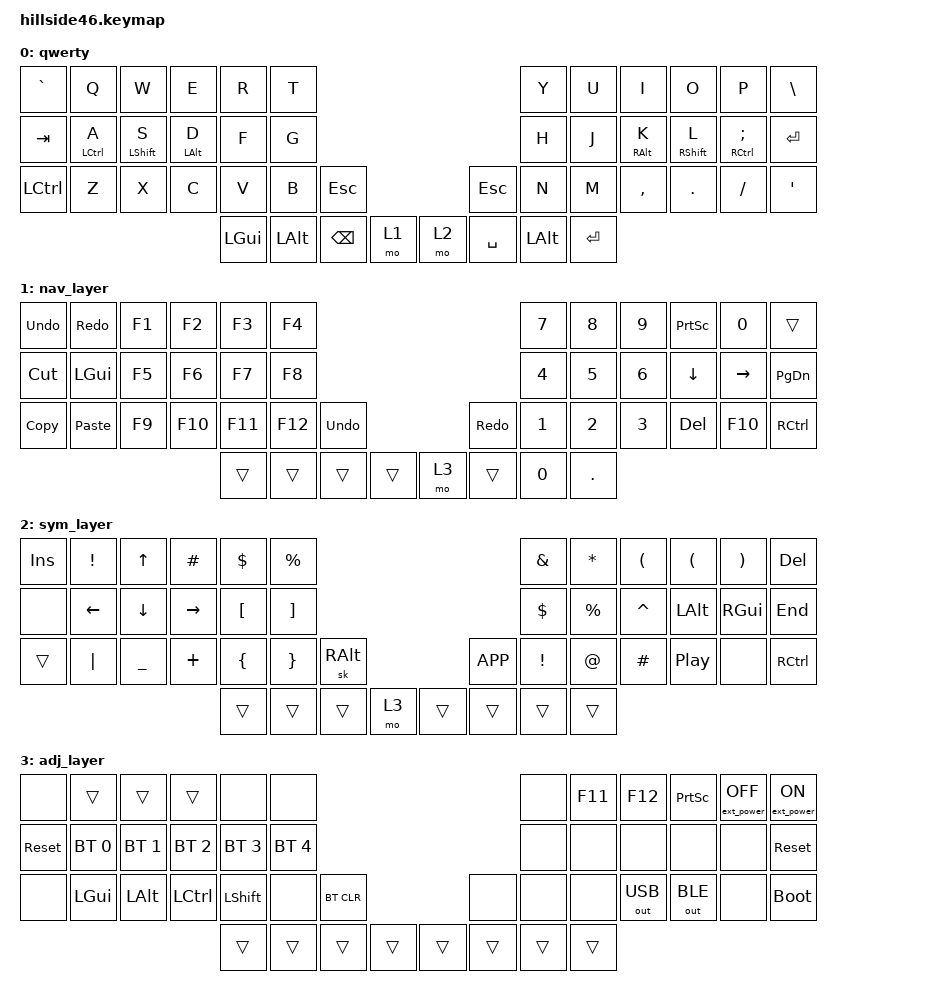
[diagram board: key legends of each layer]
/*
 * Copyright (c) 2021-2022 The ZMK Contributors
 *
 * SPDX-License-Identifier: MIT
 */

#include <behaviors.dtsi>
#include <dt-bindings/zmk/bt.h>
#include <dt-bindings/zmk/ext_power.h>
#include <dt-bindings/zmk/keys.h>
#include <dt-bindings/zmk/outputs.h>

#define Undo   LC(Z)
#define Cut    LC(X)
#define Copy   LC(C)
#define Paste  LC(V)
#define Redo   LC(Y)


/ {
	combos {
        compatible = "zmk,combos";

        lparen {
            bindings = <&kp LEFT_PARENTHESIS>;
            key-positions = <6 7>;
        };

        rparen {
            bindings = <&kp RPAR>;
            key-positions = <7 8>;
        };

        lbrace {
            bindings = <&kp LEFT_BRACE>;
            key-positions = <18 19>;
        };

        rbrace {
            bindings = <&kp RBRC>;
            key-positions = <19 20>;
        };

        lbrack {
            bindings = <&kp LEFT_BRACKET>;
            key-positions = <32 33>;
        };

        rbrack {
            bindings = <&kp RIGHT_BRACKET>;
            key-positions = <33 34>;
        };

        dash {
            bindings = <&kp MINUS>;
            key-positions = <4 5>;
        };

        underscore {
            bindings = <&kp UNDER>;
            key-positions = <16 17>;
        };

        equal {
            bindings = <&kp EQUAL>;
            key-positions = <28 29>;
        };
		
		apos {
			bindings = <&kp SQT>;
			key-positions = <20 21>;
		};
		
		quot {
			bindings = <&kp DQT>;
			key-positions = <34 35>;
		};
    };
	
	behaviors {
        hml: homerow_mods_left {
            compatible = "zmk,behavior-hold-tap";
            label = "HML";
            bindings =
                <&kp>,
                <&kp>;

            #binding-cells = <2>;
            tapping-term-ms = <200>;
            flavor = "tap-preferred";
            quick-tap-ms = <0>;
        };
        hmr: homerow_mods_right {
            compatible = "zmk,behavior-hold-tap";
            label = "HMR";
            bindings =
                <&kp>,
                <&kp>;

            #binding-cells = <2>;
            tapping-term-ms = <200>;
            flavor = "tap-preferred";
        };
    };

    keymap {
                compatible = "zmk,keymap";

                qwerty {
/* QWERTY
 * -------------------------------------------------------------------------------------------------------------------------------------
 * | `     |   Q   |   W   |   E   |   R   |   T   |-----------------------------------|   Y   |   U   |   I   |   O   |   P   | BKSPC |
 * | TAB   |   A   |   S   |   D   |   F   |   G   |-----------------------------------|   H   |   J   |   K   |   L   |   ;   | ENTER |
 * | CTRL  |   Z   |   X   |   C   |   V   |   B   |  ESC  |-------------------|  CAPS |   N   |   M   |   ,   |   .   |   /   |   '   |
 *                                 |  GUI  |  ALT  |SK SHFT|  Nav  |---|  Sym  | SPACE |  ALT  |  GUI  |
 */
                        bindings = <
&kp  GRAVE    &kp  Q        &kp  W        &kp  E        &kp  R        &kp  T                                                                         &kp Y        &kp U        &kp I        &kp O        &kp P        &kp BSLH
&kp  TAB      &hml LCTRL A  &hml LSHIFT S  &hml LALT D  &kp  F        &kp  G                                                                         &kp H        &kp J        &hmr RALT K  &hmr RSHIFT L  &hmr RCTRL SEMI&kp ENTER  
&kp  LCTRL    &kp  Z        &kp  X        &kp  C        &kp  V        &kp  B        &kp  ESC                                           &kp ESC       &kp N        &kp M        &kp COMMA    &kp DOT      &kp SLASH    &kp SQT
                                                        &kp  LGUI     &kp  LALT     &kp  BSPC   &mo 1            &mo 2    &kp SPACE    &kp LALT     &kp ENTER
                        >;
			
                        sensor-bindings = <&inc_dec_kp C_VOL_UP C_VOL_DN &inc_dec_kp PG_UP PG_DN>;
                };
		
                nav_layer {
/* NAV   
 * -------------------------------------------------------------------------------------------------------------------------------------
 * | Copy  |   1   |   2   |   3   |   4   |   5   |-----------------------------------|   6   |   7   |   8   |   9   |   0   | BSPC  |
 * | Cut   |  GUI  |  Alt  | Ctrl  | Shift | Paste |-----------------------------------| PG UP |  Left |  Up   |  Down | Right | PG DN |
 * | Ctrl  |  F1   |  F2   |  F3   |  F4   |  F5   |  UnDo |-------------------| ReDo  |  F6   |  F7   |  F8   |  F9   |  F10  | Ctrl  |
 *                                 |       |       |       |       |---| ADJ_L |       |       |       |
 */
                        bindings = <
&kp  Undo     &kp  Redo     &kp  F1       &kp  F2       &kp  F3       &kp  F4                                                                        &kp   N7   &kp  N8    &kp   N9      &kp   PRINTSCREEN  &kp  N0  &trans
&kp  Cut      &kp  LGUI     &kp  F5       &kp  F6       &kp  F7       &kp  F8                                                                        &kp   N4   &kp  N5    &kp   N6      &kp   DOWN    &kp  RIGHT    &kp PG_DN
&kp  Copy     &kp  Paste    &kp  F9       &kp  F10      &kp  F11      &kp  F12       &kp Undo                                           &kp  Redo    &kp   N1   &kp  N2    &kp   N3      &kp   DEL      &kp  F10      &kp RCTRL
                                                        &trans        &trans        &trans        &trans                 &mo 3      &trans    &kp N0        &kp DOT 
                        >;
			
                        sensor-bindings = <&inc_dec_kp PG_UP PG_DN &inc_dec_kp C_VOL_UP C_VOL_DN>;
                };

                sym_layer {
/* SYM
 * -------------------------------------------------------------------------------------------------------------------------------------
 * | INS   |   !   |   @   |   #   |   $   |   %   |-----------------------------------|   ^   |   &   |   *   |   (   |   )   | BSPC  |
 * |       |   \   |   -   |   =   |   [   |   ]   |-----------------------------------| HOME  | Shift | Ctrl  | Alt   | Gui   | END   |
 * | Ctrl  |   |   |   _   |   +   |   {   |   }   |SkAltGr|-------------------| MENU  | Mute  | Vol-  | Vol+  | Play  |       | Ctrl  |
 *                                 |       |       |       |  ADJ_L |---|      |       |       |       |
 */
                        bindings = <
&kp  INS      &kp  EXCL     &kp  UP       &kp  HASH     &kp  DOLLAR   &kp  PERCENT                                                                   &kp  AMPS    &kp  ASTRK    &kp  LPAR    &kp  LPAR     &kp  RPAR     &kp DEL
&none         &kp  LEFT     &kp  DOWN     &kp  RIGHT    &kp  LBKT     &kp  RBKT                                                                      &kp  DOLLAR  &kp  PERCENT  &kp  CARET   &kp  LALT     &kp  RGUI     &kp END
&trans        &kp  PIPE     &kp  UNDER    &kp  PLUS     &kp  LBRC     &kp  RBRC     &sk  RALT                                          &kp K_APP     &kp  EXCL    &kp  AT       &kp  HASH    &kp  C_PP     &none         &kp RCTRL
                                                        &trans        &trans        &trans       &mo  3               &trans       &trans        &trans        &trans
                        >;
			
                        sensor-bindings = <&inc_dec_kp PG_UP PG_DN &inc_dec_kp C_VOL_UP C_VOL_DN>;
                };
		
                adj_layer {
/* ADJUST
 * -------------------------------------------------------------------------------------------------------------------------------------
 * |       | QWERTY| DVORAK| COLEMK|       |       |-----------------------------------|       |  F11  |  F12  |Prt Scr|EP_OFF | EP_ON |
 * | RESET | BT 0  | BT 1  | BT 2  | BT 3  | BT 4  |-----------------------------------|       |       |       |       |       | RESET |
 * |       | LGUI  | LALT  | LCTRL | LSHIFT|       |BT CLR |-------------------|       |       |       |OUT_USB|OUT_BLE|       | BOOTL |
 *                                 |       |       |       |       |---|       |       |       |       |
 */
                        bindings = <
&none         &trans &trans &trans &none         &none                                                                             &none             &kp   F11          &kp   F12  &kp PRINTSCREEN   &ext_power EP_OFF  &ext_power EP_ON
&sys_reset    &bt  BT_SEL 0 &bt  BT_SEL 1 &bt  BT_SEL 2 &bt  BT_SEL 3 &bt  BT_SEL 4                                                                     &none             &none              &none            &none          &none           &sys_reset
&none         &kp  LGUI     &kp  LALT     &kp  LCTRL    &kp LSHIFT    &none         &bt BT_CLR                                         &none            &none             &none              &out  OUT_USB    &out  OUT_BLE  &none           &bootloader
                                                        &trans        &trans        &trans        &trans                 &trans        &trans           &trans            &trans 
                        >;
			
                        sensor-bindings = <&inc_dec_kp C_VOL_UP C_VOL_DN &inc_dec_kp PG_UP PG_DN>;
                };
        };
};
